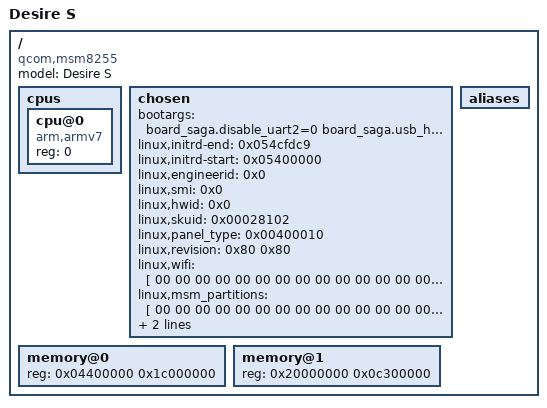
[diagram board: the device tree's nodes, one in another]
/dts-v1/;

/ {
	model = "Desire S";
	compatible = "qcom,msm8255";
	#address-cells = <0x1>;
	#size-cells = <0x1>;

	cpus {
		#address-cells = <1>;
		#size-cells = <0>;

		cpu@0 {
			device_type = "cpu";
			compatible = "arm,armv7";
			reg = <0>;
		};
	};

	chosen {
		bootargs = "board_saga.disable_uart2=0 board_saga.usb_h2w_sw=0 board_saga.disable_sdcard=0 diag.enabled=0 board_saga.debug_uart=0 smisize=0 userdata_sel=0 androidboot.emmc=true androidboot.pagesize=4096 ats=0  androidboot.lb=1 androidboot.baseband=3831.19.00.110 androidboot.cid=11111111 androidboot.batt_poweron=good_battery androidboot.carrier=ALL androidboot.mid=PG88***** androidboot.keycaps=qwerty androidboot.mode=normal androidboot.serialno=xxxxxxxxxxxx androidboot.bootloader=2.02.0002 zygote_oneshot=off msm_watchdog.enable=1 kmemleak=off no_console_suspend=1 androidboot.selinux=permissive androidboot.hardware=htc7x30";
		linux,initrd-end = <0x054cfdc9>;
		linux,initrd-start = <0x05400000>;
		linux,engineerid = <0x0>;
		linux,smi = <0x0>;
		linux,hwid = <0x0>;
		linux,skuid = <0x00028102>;
		linux,panel_type = <0x00400010>;
		linux,revision = <0x80 0x80>;
		linux,wifi = [
			00 00 00 00 00 00 00 00 00 00 00 00 00 00 00 00
			00 00 00 00 00 00 00 00 00 00 00 00 00 00 00 00
			00 00 00 00 00 00 00 00 00 00 00 00 00 00 00 00
			00 00 00 00 00 00 00 00 00 00 00 00 00 00 00 00
			00 00 00 00 00 00 00 00 00 00 00 00 00 00 00 00
			00 00 00 00 00 00 00 00 00 00 00 00 00 00 00 00
			00 00 00 00 00 00 00 00 00 00 00 00 00 00 00 00
			00 00 00 00 00 00 00 00 00 00 00 00 00 00 00 00
			00 00 00 00 00 00 00 00 00 00 00 00 00 00 00 00
			00 00 00 00 00 00 00 00 00 00 00 00 00 00 00 00
			00 00 00 00 00 00 00 00 00 00 00 00 00 00 00 00
			00 00 00 00 00 00 00 00 00 00 00 00 00 00 00 00
			00 00 00 00 00 00 00 00 00 00 00 00 00 00 00 00
			00 00 00 00 00 00 00 00 00 00 00 00 00 00 00 00
			00 00 00 00 00 00 00 00 00 00 00 00 00 00 00 00
			00 00 00 00 00 00 00 00 00 00 00 00 00 00 00 00
			00 00 00 00 00 00 00 00 00 00 00 00 00 00 00 00
			00 00 00 00 00 00 00 00 00 00 00 00 00 00 00 00
			00 00 00 00 00 00 00 00 00 00 00 00 00 00 00 00
			00 00 00 00 00 00 00 00 00 00 00 00 00 00 00 00
			00 00 00 00 00 00 00 00 00 00 00 00 00 00 00 00
			00 00 00 00 00 00 00 00 00 00 00 00 00 00 00 00
			00 00 00 00 00 00 00 00 00 00 00 00 00 00 00 00
			00 00 00 00 00 00 00 00 00 00 00 00 00 00 00 00
			00 00 00 00 00 00 00 00 00 00 00 00 00 00 00 00
			00 00 00 00 00 00 00 00 00 00 00 00 00 00 00 00
			00 00 00 00 00 00 00 00 00 00 00 00 00 00 00 00
			00 00 00 00 00 00 00 00 00 00 00 00 00 00 00 00
			00 00 00 00 00 00 00 00 00 00 00 00 00 00 00 00
			00 00 00 00 00 00 00 00 00 00 00 00 00 00 00 00
			00 00 00 00 00 00 00 00 00 00 00 00 00 00 00 00
			00 00 00 00 00 00 00 00 00 00 00 00 00 00 00 00
			00 00 00 00 00 00 00 00 00 00 00 00 00 00 00 00
			00 00 00 00 00 00 00 00 00 00 00 00 00 00 00 00
			00 00 00 00 00 00 00 00 00 00 00 00 00 00 00 00
			00 00 00 00 00 00 00 00 00 00 00 00 00 00 00 00
			00 00 00 00 00 00 00 00 00 00 00 00 00 00 00 00
			00 00 00 00 00 00 00 00 00 00 00 00 00 00 00 00
			00 00 00 00 00 00 00 00 00 00 00 00 00 00 00 00
			00 00 00 00 00 00 00 00 00 00 00 00 00 00 00 00
			00 00 00 00 00 00 00 00 00 00 00 00 00 00 00 00
			00 00 00 00 00 00 00 00 00 00 00 00 00 00 00 00
			00 00 00 00 00 00 00 00 00 00 00 00 00 00 00 00
			00 00 00 00 00 00 00 00 00 00 00 00 00 00 00 00
			00 00 00 00 00 00 00 00 00 00 00 00 00 00 00 00
			00 00 00 00 00 00 00 00 00 00 00 00 00 00 00 00
			00 00 00 00 00 00 00 00 00 00 00 00 00 00 00 00
			00 00 00 00 00 00 00 00 00 00 00 00 00 00 00 00
			00 00 00 00 00 00 00 00 00 00 00 00 00 00 00 00
			00 00 00 00 00 00 00 00 00 00 00 00 00 00 00 00
			00 00 00 00 00 00 00 00 00 00 00 00 00 00 00 00
			00 00 00 00 00 00 00 00 00 00 00 00 00 00 00 00
			00 00 00 00 00 00 00 00 00 00 00 00 00 00 00 00
			00 00 00 00 00 00 00 00 00 00 00 00 00 00 00 00
			00 00 00 00 00 00 00 00 00 00 00 00 00 00 00 00
			00 00 00 00 00 00 00 00 00 00 00 00 00 00 00 00
			00 00 00 00 00 00 00 00 00 00 00 00 00 00 00 00
			00 00 00 00 00 00 00 00 00 00 00 00 00 00 00 00
			00 00 00 00 00 00 00 00 00 00 00 00 00 00 00 00
			00 00 00 00 00 00 00 00 00 00 00 00 00 00 00 00
			00 00 00 00 00 00 00 00 00 00 00 00 00 00 00 00
			00 00 00 00 00 00 00 00 00 00 00 00 00 00 00 00
			00 00 00 00 00 00 00 00 00 00 00 00 00 00 00 00
			00 00 00 00 00 00 00 00 00 00 00 00 00 00 00 00
			00 00 00 00 00 00 00 00 00 00 00 00 00 00 00 00
			00 00 00 00 00 00 00 00 00 00 00 00 00 00 00 00
			00 00 00 00 00 00 00 00 00 00 00 00 00 00 00 00
			00 00 00 00 00 00 00 00 00 00 00 00 00 00 00 00
			00 00 00 00 00 00 00 00 00 00 00 00 00 00 00 00
			00 00 00 00 00 00 00 00 00 00 00 00 00 00 00 00
			00 00 00 00 00 00 00 00 00 00 00 00 00 00 00 00
			00 00 00 00 00 00 00 00 00 00 00 00 00 00 00 00
			00 00 00 00 00 00 00 00 00 00 00 00 00 00 00 00
			00 00 00 00 00 00 00 00 00 00 00 00 00 00 00 00
			00 00 00 00 00 00 00 00 00 00 00 00 00 00 00 00
			00 00 00 00 00 00 00 00 00 00 00 00 00 00 00 00
			00 00 00 00 00 00 00 00 00 00 00 00 00 00 00 00
			00 00 00 00 00 00 00 00 00 00 00 00 00 00 00 00
			00 00 00 00 00 00 00 00 00 00 00 00 00 00 00 00
			00 00 00 00 00 00 00 00 00 00 00 00 00 00 00 00
			00 00 00 00 00 00 00 00 00 00 00 00 00 00 00 00
			00 00 00 00 00 00 00 00 00 00 00 00 00 00 00 00
			00 00 00 00 00 00 00 00 00 00 00 00 00 00 00 00
			00 00 00 00 00 00 00 00 00 00 00 00 00 00 00 00
			00 00 00 00 00 00 00 00 00 00 00 00 00 00 00 00
			00 00 00 00 00 00 00 00 00 00 00 00 00 00 00 00
			00 00 00 00 00 00 00 00 00 00 00 00 00 00 00 00
			00 00 00 00 00 00 00 00 00 00 00 00 00 00 00 00
			00 00 00 00 00 00 00 00 00 00 00 00 00 00 00 00
			00 00 00 00 00 00 00 00 00 00 00 00 00 00 00 00
			00 00 00 00 00 00 00 00 00 00 00 00 00 00 00 00
			00 00 00 00 00 00 00 00 00 00 00 00 00 00 00 00
			00 00 00 00 00 00 00 00 00 00 00 00 00 00 00 00
			00 00 00 00 00 00 00 00 00 00 00 00 00 00 00 00
			00 00 00 00 00 00 00 00 00 00 00 00 00 00 00 00
			00 00 00 00 00 00 00 00 00 00 00 00 00 00 00 00
			00 00 00 00 00 00 00 00 00 00 00 00 00 00 00 00
			00 00 00 00 00 00 00 00 00 00 00 00 00 00 00 00
			00 00 00 00 00 00 00 00 00 00 00 00 00 00 00 00
			00 00 00 00 00 00 00 00 00 00 00 00 00 00 00 00
			00 00 00 00 00 00 00 00 00 00 00 00 00 00 00 00
			00 00 00 00 00 00 00 00 00 00 00 00 00 00 00 00
			00 00 00 00 00 00 00 00 00 00 00 00 00 00 00 00
			00 00 00 00 00 00 00 00 00 00 00 00 00 00 00 00
			00 00 00 00 00 00 00 00 00 00 00 00 00 00 00 00
			00 00 00 00 00 00 00 00 00 00 00 00 00 00 00 00
			00 00 00 00 00 00 00 00 00 00 00 00 00 00 00 00
			00 00 00 00 00 00 00 00 00 00 00 00 00 00 00 00
			00 00 00 00 00 00 00 00 00 00 00 00 00 00 00 00
			00 00 00 00 00 00 00 00 00 00 00 00 00 00 00 00
			00 00 00 00 00 00 00 00 00 00 00 00 00 00 00 00
			00 00 00 00 00 00 00 00 00 00 00 00 00 00 00 00
			00 00 00 00 00 00 00 00 00 00 00 00 00 00 00 00
			00 00 00 00 00 00 00 00 00 00 00 00 00 00 00 00
			00 00 00 00 00 00 00 00 00 00 00 00 00 00 00 00
			00 00 00 00 00 00 00 00 00 00 00 00 00 00 00 00
			00 00 00 00 00 00 00 00 00 00 00 00 00 00 00 00
			00 00 00 00 00 00 00 00 00 00 00 00 00 00 00 00
			00 00 00 00 00 00 00 00 00 00 00 00 00 00 00 00
			00 00 00 00 00 00 00 00 00 00 00 00 00 00 00 00
			00 00 00 00 00 00 00 00 00 00 00 00 00 00 00 00
			00 00 00 00 00 00 00 00 00 00 00 00 00 00 00 00
			00 00 00 00 00 00 00 00 00 00 00 00 00 00 00 00
			00 00 00 00 00 00 00 00 00 00 00 00 00 00 00 00
			00 00 00 00 00 00 00 00 00 00 00 00 00 00 00 00
			00 00 00 00 00 00 00 00 00 00 00 00 00 00 00 00
			00 00 00 00 00 00 00 00 00 00 00 00 00 00 00 00
			00 00 00 00 00 00 00 00 00 00 00 00 00 00 00 00
		];
		linux,msm_partitions = [
			00 00 00 00 00 00 00 00 00 00 00 00 00 00 00 00
			00 00 00 00 00 00 00 00 00 00 00 00 00 00 00 00
			00 00 00 00 00 00 00 00 00 00 00 00 00 00 00 00
			00 00 00 00 00 00 00 00 00 00 00 00 00 00 00 00
			00 00 00 00 00 00 00 00 00 00 00 00 00 00 00 00
			00 00 00 00 00 00 00 00 00 00 00 00 00 00 00 00
			00 00 00 00 00 00 00 00 00 00 00 00 00 00 00 00
			00 00 00 00 00 00 00 00 00 00 00 00 00 00 00 00
			00 00 00 00 00 00 00 00 00 00 00 00 00 00 00 00
			00 00 00 00 00 00 00 00 00 00 00 00 00 00 00 00
			00 00 00 00 00 00 00 00 00 00 00 00 00 00 00 00
			00 00 00 00 00 00 00 00 00 00 00 00 00 00 00 00
			00 00 00 00 1d 00 00 00 00 00 00 00 00 00 00 00
		];
		linux,ps_type = <0x00000000>;
		linux,pcbid = <0x00000000>;
	};

	aliases {
	};

	memory@0 {
		device_type = "memory";
		reg = <0x04400000 0x1c000000>;
	};

	memory@1 {
		device_type = "memory";
		reg = <0x20000000 0x0c300000>;
	};
};
